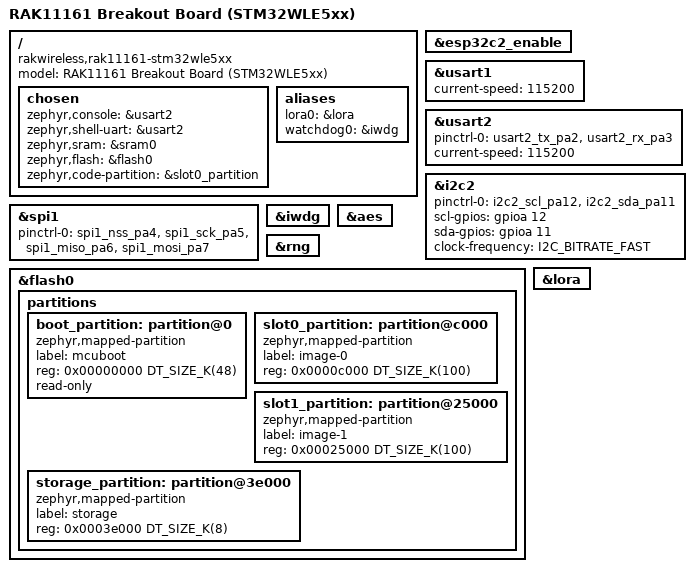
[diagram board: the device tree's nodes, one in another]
/*
 * Copyright (c) 2026 RAKwireless Technology Limited <www.rakwireless.com>
 * Sercan Erat <sercanerat@gmail.com>
 * JaeHwan Jin <jaehwan.jin@rakwireless.com>
 * SPDX-License-Identifier: Apache-2.0
 */

/dts-v1/;
#include <rakwireless/rak11160_stm32wle5xx.dtsi>

/ {
	model = "RAK11161 Breakout Board (STM32WLE5xx)";
	compatible = "rakwireless,rak11161-stm32wle5xx";

	chosen {
		zephyr,console = &usart2;
		zephyr,shell-uart = &usart2;
		zephyr,sram = &sram0;
		zephyr,flash = &flash0;
		zephyr,code-partition = &slot0_partition;
	};

	aliases {
		lora0 = &lora;
		watchdog0 = &iwdg;
	};
};

&esp32c2_enable {
	status = "okay";
};

/*
 * Common board-level label for
 * the on-module STM32WLE5 <-> ESP32-C2 coprocessor UART link.
 */
coproc_uart: &usart1 {
	current-speed = <115200>;
	status = "okay";
};

&usart2 {
	pinctrl-0 = <&usart2_tx_pa2 &usart2_rx_pa3>;
	pinctrl-names = "default";
	current-speed = <115200>;
	status = "okay";
};

&i2c2 {
	pinctrl-0 = <&i2c2_scl_pa12 &i2c2_sda_pa11>;
	pinctrl-names = "default";
	scl-gpios = <&gpioa 12 GPIO_ACTIVE_HIGH>;
	sda-gpios = <&gpioa 11 GPIO_ACTIVE_HIGH>;
	status = "okay";
	clock-frequency = <I2C_BITRATE_FAST>;
};

&spi1 {
	pinctrl-0 = <&spi1_nss_pa4 &spi1_sck_pa5
		     &spi1_miso_pa6 &spi1_mosi_pa7>;
	pinctrl-names = "default";
	status = "okay";
};

&iwdg {
	status = "okay";
};

&aes {
	status = "okay";
};

&rng {
	status = "okay";
};

&flash0 {
	partitions {
		ranges;
		#address-cells = <1>;
		#size-cells = <1>;

		boot_partition: partition@0 {
			compatible = "zephyr,mapped-partition";
			label = "mcuboot";
			reg = <0x00000000 DT_SIZE_K(48)>;
			read-only;
		};

		slot0_partition: partition@c000 {
			compatible = "zephyr,mapped-partition";
			label = "image-0";
			reg = <0x0000c000 DT_SIZE_K(100)>;
		};

		slot1_partition: partition@25000 {
			compatible = "zephyr,mapped-partition";
			label = "image-1";
			reg = <0x00025000 DT_SIZE_K(100)>;
		};

		storage_partition: partition@3e000 {
			compatible = "zephyr,mapped-partition";
			label = "storage";
			reg = <0x0003e000 DT_SIZE_K(8)>;
		};
	};
};

&lora {
	status = "okay";
};
